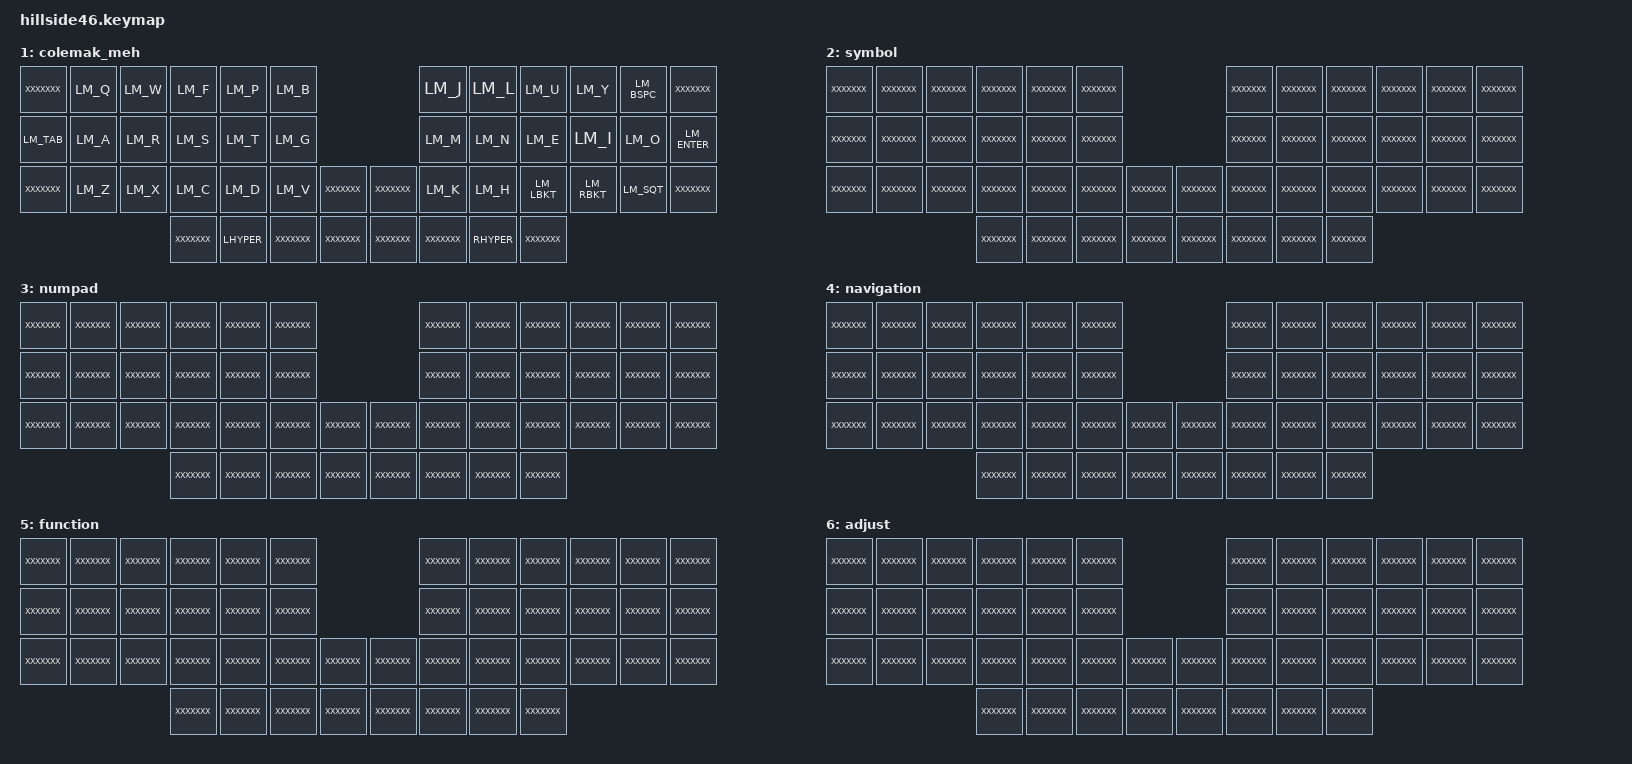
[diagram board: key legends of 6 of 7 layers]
#include "base.keymap"
#include <dt-bindings/zmk/bt.h>
#include <dt-bindings/zmk/ext_power.h>

/ {
  keymap {
    compatible = "zmk,keymap";

    colemak {
      bindings = <

/*  ┌─────────┬─────────┬─────────┬─────────┬─────────┬─────────┐                      ┌─────────┬─────────┬─────────┬─────────┬─────────┬─────────┐  */
      &kp TAB    &kp Q     &kp W     &kp F     &kp P     &kp B                            &kp J     &kp L     &kp U     &kp Y   &kp SEMI   &kp SQT
/*  ├─────────┼─────────┼─────────┼─────────┼─────────┼─────────┤                      ├─────────┼─────────┼─────────┼─────────┼─────────┼─────────┤  */
     &kp BSPC    MT_A      &kp R     &kp S     &kp T     &kp G                            &kp M     &kp N     &kp E     &kp I     MT_O    &kp ENTER
/*  ├─────────┼─────────┼─────────┼─────────┼─────────┼─────────┼─────────┐  ┌─────────┼─────────┼─────────┼─────────┼─────────┼─────────┼─────────┤  */
      XXXXXXX    &kp Z     &kp X     &kp C     &kp D     &kp V     XXXXXXX      XXXXXXX   &kp K     &kp H   &kp COMMA  &kp DOT  &kp SLASH  XXXXXXX
/*  └─────────┴─────────┴─────────┼─────────┼─────────┼─────────┼─────────┤  ├─────────┼─────────┼─────────┼─────────┼─────────┴─────────┴─────────┘  */
                                    _______  MT_SPACE  &bt BT_PRV XXXXXXX      XXXXXXX  &bt BT_NXT MT_ESC    _______
/*                                └─────────┴─────────┴─────────┴─────────┘  └─────────┴─────────┴─────────┴─────────┘                                */
      >;
    };

    colemak_meh {
      bindings = <

/*  ┌─────────┬─────────┬─────────┬─────────┬─────────┬─────────┐                      ┌─────────┬─────────┬─────────┬─────────┬─────────┬─────────┐  */
      XXXXXXX    LM_Q      LM_W      LM_F      LM_P      LM_B                             LM_J      LM_L      LM_U      LM_Y     LM_BSPC   XXXXXXX
/*  ├─────────┼─────────┼─────────┼─────────┼─────────┼─────────┤                      ├─────────┼─────────┼─────────┼─────────┼─────────┼─────────┤  */
      LM_TAB     LM_A      LM_R      LM_S      LM_T      LM_G                             LM_M      LM_N      LM_E      LM_I      LM_O    LM_ENTER
/*  ├─────────┼─────────┼─────────┼─────────┼─────────┼─────────┼─────────┐  ┌─────────┼─────────┼─────────┼─────────┼─────────┼─────────┼─────────┤  */
      XXXXXXX    LM_Z      LM_X      LM_C      LM_D      LM_V     XXXXXXX      XXXXXXX    LM_K      LM_H     LM_LBKT   LM_RBKT   LM_SQT    XXXXXXX
/*  └─────────┴─────────┴─────────┼─────────┼─────────┼─────────┼─────────┤  ├─────────┼─────────┼─────────┼─────────┼─────────┴─────────┴─────────┘  */
                                    XXXXXXX   LHYPER    XXXXXXX   XXXXXXX      XXXXXXX   XXXXXXX   RHYPER    XXXXXXX
/*                                └─────────┴─────────┴─────────┴─────────┘  └─────────┴─────────┴─────────┴─────────┘                                */
      >;
    };

    symbol {
      bindings = <

/*  ┌─────────┬─────────┬─────────┬─────────┬─────────┬─────────┐                      ┌─────────┬─────────┬─────────┬─────────┬─────────┬─────────┐  */
      XXXXXXX   XXXXXXX   XXXXXXX   XXXXXXX   XXXXXXX   XXXXXXX                          XXXXXXX   XXXXXXX   XXXXXXX   XXXXXXX   XXXXXXX   XXXXXXX
/*  ├─────────┼─────────┼─────────┼─────────┼─────────┼─────────┤                      ├─────────┼─────────┼─────────┼─────────┼─────────┼─────────┤  */
      XXXXXXX   XXXXXXX   XXXXXXX   XXXXXXX   XXXXXXX   XXXXXXX                          XXXXXXX   XXXXXXX   XXXXXXX   XXXXXXX   XXXXXXX   XXXXXXX
/*  ├─────────┼─────────┼─────────┼─────────┼─────────┼─────────┼─────────┐  ┌─────────┼─────────┼─────────┼─────────┼─────────┼─────────┼─────────┤  */
      XXXXXXX   XXXXXXX   XXXXXXX   XXXXXXX   XXXXXXX   XXXXXXX   XXXXXXX      XXXXXXX   XXXXXXX   XXXXXXX   XXXXXXX   XXXXXXX   XXXXXXX   XXXXXXX
/*  └─────────┴─────────┴─────────┼─────────┼─────────┼─────────┼─────────┤  ├─────────┼─────────┼─────────┼─────────┼─────────┴─────────┴─────────┘  */
                                    XXXXXXX   XXXXXXX   XXXXXXX   XXXXXXX      XXXXXXX   XXXXXXX   XXXXXXX   XXXXXXX
/*                                └─────────┴─────────┴─────────┴─────────┘  └─────────┴─────────┴─────────┴─────────┘                                */
      >;
    };

    numpad {
      bindings = <

/*  ┌─────────┬─────────┬─────────┬─────────┬─────────┬─────────┐                      ┌─────────┬─────────┬─────────┬─────────┬─────────┬─────────┐  */
      XXXXXXX   XXXXXXX   XXXXXXX   XXXXXXX   XXXXXXX   XXXXXXX                          XXXXXXX   XXXXXXX   XXXXXXX   XXXXXXX   XXXXXXX   XXXXXXX
/*  ├─────────┼─────────┼─────────┼─────────┼─────────┼─────────┤                      ├─────────┼─────────┼─────────┼─────────┼─────────┼─────────┤  */
      XXXXXXX   XXXXXXX   XXXXXXX   XXXXXXX   XXXXXXX   XXXXXXX                          XXXXXXX   XXXXXXX   XXXXXXX   XXXXXXX   XXXXXXX   XXXXXXX
/*  ├─────────┼─────────┼─────────┼─────────┼─────────┼─────────┼─────────┐  ┌─────────┼─────────┼─────────┼─────────┼─────────┼─────────┼─────────┤  */
      XXXXXXX   XXXXXXX   XXXXXXX   XXXXXXX   XXXXXXX   XXXXXXX   XXXXXXX      XXXXXXX   XXXXXXX   XXXXXXX   XXXXXXX   XXXXXXX   XXXXXXX   XXXXXXX
/*  └─────────┴─────────┴─────────┼─────────┼─────────┼─────────┼─────────┤  ├─────────┼─────────┼─────────┼─────────┼─────────┴─────────┴─────────┘  */
                                    XXXXXXX   XXXXXXX   XXXXXXX   XXXXXXX      XXXXXXX   XXXXXXX   XXXXXXX   XXXXXXX
/*                                └─────────┴─────────┴─────────┴─────────┘  └─────────┴─────────┴─────────┴─────────┘                                */
      >;
    };

    navigation {
      bindings = <

/*  ┌─────────┬─────────┬─────────┬─────────┬─────────┬─────────┐                      ┌─────────┬─────────┬─────────┬─────────┬─────────┬─────────┐  */
      XXXXXXX   XXXXXXX   XXXXXXX   XXXXXXX   XXXXXXX   XXXXXXX                          XXXXXXX   XXXXXXX   XXXXXXX   XXXXXXX   XXXXXXX   XXXXXXX
/*  ├─────────┼─────────┼─────────┼─────────┼─────────┼─────────┤                      ├─────────┼─────────┼─────────┼─────────┼─────────┼─────────┤  */
      XXXXXXX   XXXXXXX   XXXXXXX   XXXXXXX   XXXXXXX   XXXXXXX                          XXXXXXX   XXXXXXX   XXXXXXX   XXXXXXX   XXXXXXX   XXXXXXX
/*  ├─────────┼─────────┼─────────┼─────────┼─────────┼─────────┼─────────┐  ┌─────────┼─────────┼─────────┼─────────┼─────────┼─────────┼─────────┤  */
      XXXXXXX   XXXXXXX   XXXXXXX   XXXXXXX   XXXXXXX   XXXXXXX   XXXXXXX      XXXXXXX   XXXXXXX   XXXXXXX   XXXXXXX   XXXXXXX   XXXXXXX   XXXXXXX
/*  └─────────┴─────────┴─────────┼─────────┼─────────┼─────────┼─────────┤  ├─────────┼─────────┼─────────┼─────────┼─────────┴─────────┴─────────┘  */
                                    XXXXXXX   XXXXXXX   XXXXXXX   XXXXXXX      XXXXXXX   XXXXXXX   XXXXXXX   XXXXXXX
/*                                └─────────┴─────────┴─────────┴─────────┘  └─────────┴─────────┴─────────┴─────────┘                                */
      >;
    };

    function {
      bindings = <

/*  ┌─────────┬─────────┬─────────┬─────────┬─────────┬─────────┐                      ┌─────────┬─────────┬─────────┬─────────┬─────────┬─────────┐  */
      XXXXXXX   XXXXXXX   XXXXXXX   XXXXXXX   XXXXXXX   XXXXXXX                          XXXXXXX   XXXXXXX   XXXXXXX   XXXXXXX   XXXXXXX   XXXXXXX
/*  ├─────────┼─────────┼─────────┼─────────┼─────────┼─────────┤                      ├─────────┼─────────┼─────────┼─────────┼─────────┼─────────┤  */
      XXXXXXX   XXXXXXX   XXXXXXX   XXXXXXX   XXXXXXX   XXXXXXX                          XXXXXXX   XXXXXXX   XXXXXXX   XXXXXXX   XXXXXXX   XXXXXXX
/*  ├─────────┼─────────┼─────────┼─────────┼─────────┼─────────┼─────────┐  ┌─────────┼─────────┼─────────┼─────────┼─────────┼─────────┼─────────┤  */
      XXXXXXX   XXXXXXX   XXXXXXX   XXXXXXX   XXXXXXX   XXXXXXX   XXXXXXX      XXXXXXX   XXXXXXX   XXXXXXX   XXXXXXX   XXXXXXX   XXXXXXX   XXXXXXX
/*  └─────────┴─────────┴─────────┼─────────┼─────────┼─────────┼─────────┤  ├─────────┼─────────┼─────────┼─────────┼─────────┴─────────┴─────────┘  */
                                    XXXXXXX   XXXXXXX   XXXXXXX   XXXXXXX      XXXXXXX   XXXXXXX   XXXXXXX   XXXXXXX
/*                                └─────────┴─────────┴─────────┴─────────┘  └─────────┴─────────┴─────────┴─────────┘                                */
      >;
    };

    adjust {
      bindings = <

/*  ┌─────────┬─────────┬─────────┬─────────┬─────────┬─────────┐                      ┌─────────┬─────────┬─────────┬─────────┬─────────┬─────────┐  */
      XXXXXXX   XXXXXXX   XXXXXXX   XXXXXXX   XXXXXXX   XXXXXXX                          XXXXXXX   XXXXXXX   XXXXXXX   XXXXXXX   XXXXXXX   XXXXXXX
/*  ├─────────┼─────────┼─────────┼─────────┼─────────┼─────────┤                      ├─────────┼─────────┼─────────┼─────────┼─────────┼─────────┤  */
      XXXXXXX   XXXXXXX   XXXXXXX   XXXXXXX   XXXXXXX   XXXXXXX                          XXXXXXX   XXXXXXX   XXXXXXX   XXXXXXX   XXXXXXX   XXXXXXX
/*  ├─────────┼─────────┼─────────┼─────────┼─────────┼─────────┼─────────┐  ┌─────────┼─────────┼─────────┼─────────┼─────────┼─────────┼─────────┤  */
      XXXXXXX   XXXXXXX   XXXXXXX   XXXXXXX   XXXXXXX   XXXXXXX   XXXXXXX      XXXXXXX   XXXXXXX   XXXXXXX   XXXXXXX   XXXXXXX   XXXXXXX   XXXXXXX
/*  └─────────┴─────────┴─────────┼─────────┼─────────┼─────────┼─────────┤  ├─────────┼─────────┼─────────┼─────────┼─────────┴─────────┴─────────┘  */
                                    XXXXXXX   XXXXXXX   XXXXXXX   XXXXXXX      XXXXXXX   XXXXXXX   XXXXXXX   XXXXXXX
/*                                └─────────┴─────────┴─────────┴─────────┘  └─────────┴─────────┴─────────┴─────────┘                                */
      >;
    };
  };
};
